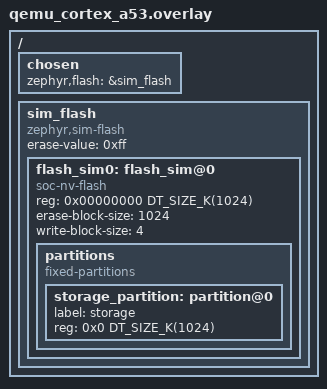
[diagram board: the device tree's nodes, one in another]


/ {
	chosen {
		zephyr,flash = &sim_flash;
	};

	sim_flash: sim_flash {
		compatible = "zephyr,sim-flash";

		#address-cells = <1>;
		#size-cells = <1>;
		erase-value = <0xff>;

		flash_sim0: flash_sim@0 {
			compatible = "soc-nv-flash";
			reg = <0x00000000 DT_SIZE_K(1024)>;

			erase-block-size = <1024>;
			write-block-size = <4>;
			partitions {
				#address-cells = <1>;
				#size-cells = <1>;
				compatible = "fixed-partitions";

				storage_partition: partition@0 {
					label = "storage";
					reg = <0x0 DT_SIZE_K(1024)>;
				};
			};
		};
	};
};
